AUTOSAR XML (schema 00048)
standard types defined: uint8, uint8_DataConstr
package /ComponentTypes
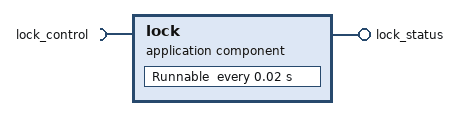
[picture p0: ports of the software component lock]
  application sw component type lock
    provide port lock_status: nonqueued-sender-com-spec{data-element=lock_status, init-value=0}, provided-interface=lock_status
    require port lock_control: nonqueued-receiver-com-spec{data-element=lock_cmd, filter=data-filter-type=ALWAYS, init-value=0}, required-interface=lock_control
    behavior lock_InternalBehavior
      timing event TMT_Runnable: start-on-event=Runnable, period=0.02
      runnable Runnable: minimum-start-interval=0.02
        data-receive-point-by-arguments:
          access REC_lock_control_lock_cmd: accessed-variable=lock_control.lock_cmd
        data-send-points:
          access SEND_lock_status_lock_status: accessed-variable=lock_status.lock_status
  swc implementation lock_Implementation: behavior=lock_InternalBehavior
    code-descriptors:
      code Default: artifact-descriptors=autosar-engineering-object={short-label=Default, category=SWSRC}
package /PortInterfaces
  sender receiver interface lock_control: invalidation-policy{data-element=lock_cmd, handle-invalid=DONT-INVALIDATE}
    data lock_cmd: type=uint8
  sender receiver interface lock_status: invalidation-policy{data-element=lock_status, handle-invalid=DONT-INVALIDATE}
    data lock_status: type=uint8
